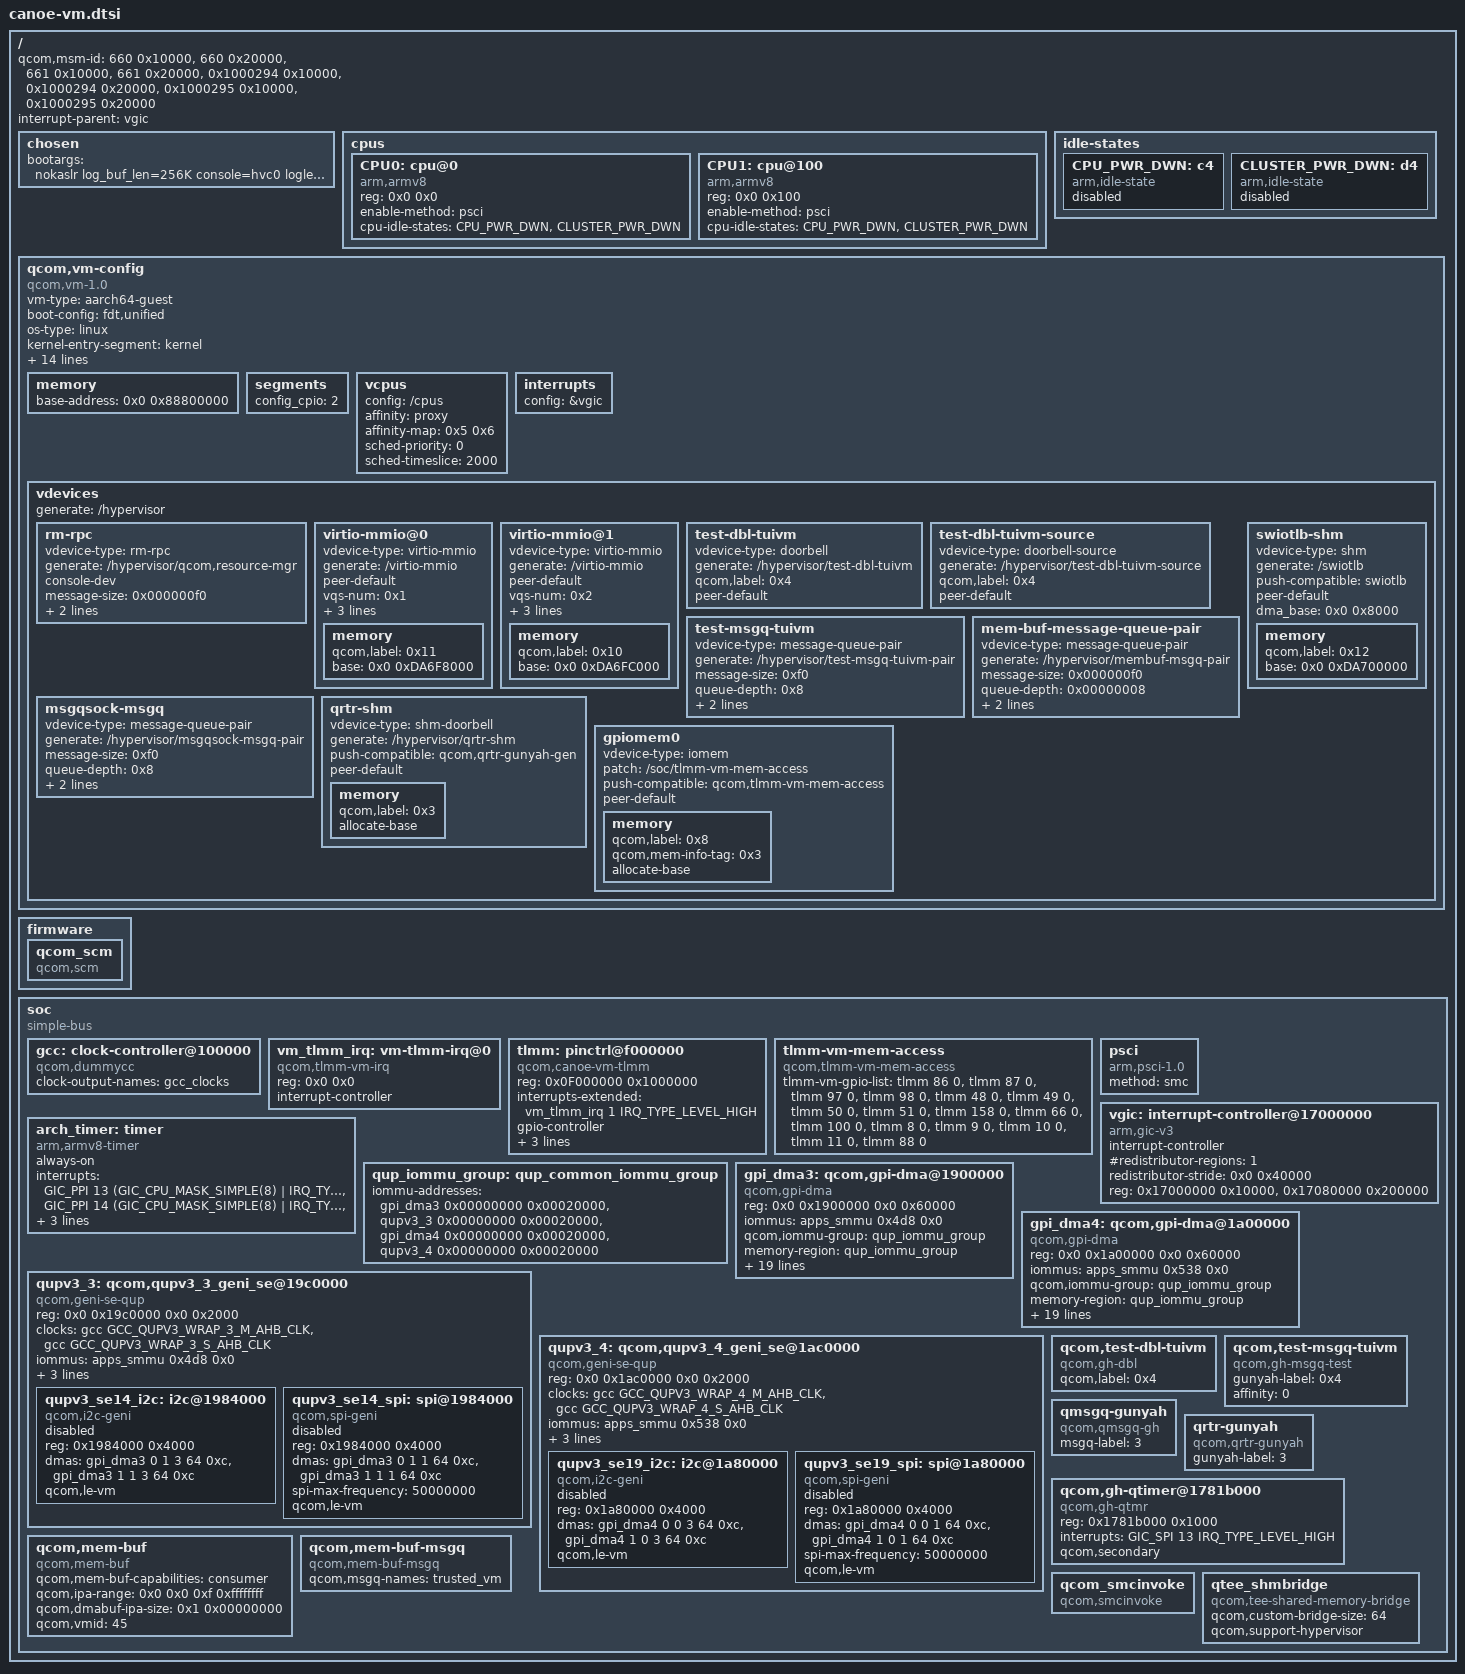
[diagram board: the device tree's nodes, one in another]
// SPDX-License-Identifier: BSD-3-Clause
/*
 * Copyright (c) 2024 Qualcomm Innovation Center, Inc. All rights reserved.
 */

#include <dt-bindings/clock/qcom,gcc-canoe.h>
#include <dt-bindings/interrupt-controller/arm-gic.h>

/ {
	#address-cells = <0x2>;
	#size-cells = <0x2>;
	qcom,msm-id = <660 0x10000>, <660 0x20000>, <661 0x10000>, <661 0x20000>,
		      <0x1000294 0x10000>, <0x1000294 0x20000>,
		      <0x1000295 0x10000>, <0x1000295 0x20000>;
	interrupt-parent = <&vgic>;

	chosen {
		bootargs = "nokaslr log_buf_len=256K console=hvc0 loglevel=8 swiotlb=noforce";
	};

	cpus {
		#address-cells = <0x2>;
		#size-cells = <0x0>;

		CPU0: cpu@0 {
			compatible = "arm,armv8";
			reg = <0x0 0x0>;
			device_type = "cpu";
			enable-method = "psci";
			cpu-idle-states = <&CPU_PWR_DWN
					   &CLUSTER_PWR_DWN>;
		};

		CPU1: cpu@100 {
			compatible = "arm,armv8";
			reg = <0x0 0x100>;
			device_type = "cpu";
			enable-method = "psci";
			cpu-idle-states = <&CPU_PWR_DWN
					   &CLUSTER_PWR_DWN>;

		};
	};

	idle-states {
		CPU_PWR_DWN: c4 {  /* Using Gold C4 latencies */
			compatible = "arm,idle-state";
			status = "disabled";
		};

		CLUSTER_PWR_DWN: d4 { /* C4+D4 */
			compatible = "arm,idle-state";
			status = "disabled";
		};
	};

	qcom,vm-config {
		compatible = "qcom,vm-1.0";
		vm-type = "aarch64-guest";
		boot-config = "fdt,unified";
		os-type = "linux";
		kernel-entry-segment = "kernel";
		kernel-entry-offset = <0x0 0x0>;
		vendor = "QTI";
		image-name = "qcom,trustedvm";
		qcom,pasid = <0x0 0x1c>;
		qcom,qtee-config-info = "p=3,9,39,77,78,7C,8F,97,C8,FE,11B,159,199,47E,7F1,CDF;";
		qcom,secdomain-ids = <45>;
		qcom,primary-vm-index = <0>;
		vm-uri = "vmuid/trusted-ui";
		vm-guid = "598085da-c516-5b25-a9c1-927a02819770";

		vm-attrs = "crash-fatal", "context-dump";

		iomemory-ranges = <0x0 0x1924000 0x0 0x1924000 0x0 0x4000 0x0
				0x0 0x1a24000 0x0 0x1a24000 0x0 0x4000 0x0>;

		/* For LEVM por usecases are QUP3_SE1 and QUP4_SE0.
		 * QUP3: SE1: GPII5 : IRQ_625
		 * QUP4: SE0: GPII5 : IRQ_541
		 */
		gic-irq-ranges = <541 541
				  625 625>; /* PVM->SVM IRQ transfer */

		memory {
			#address-cells = <0x2>;
			#size-cells = <0x0>;
			/*
			 * IPA address linux image is loaded at. Must be within
			 * first 1GB due to memory hotplug requirement.
			 */
			base-address = <0x0 0x88800000 >;
		};

		segments {
			config_cpio = <2>;
		};

		vcpus {
			config = "/cpus";
			affinity = "proxy";
			affinity-map = <0x5 0x6>;
			sched-priority = <0>;       /* relative to PVM */
			sched-timeslice = <2000>;   /* in ms */
		};

		interrupts {
			config = &vgic;
		};

		vdevices {
			generate = "/hypervisor";

			rm-rpc {
				vdevice-type = "rm-rpc";
				generate = "/hypervisor/qcom,resource-mgr";
				console-dev;
				message-size = <0x000000f0>;
				queue-depth = <0x00000008>;
				qcom,label = <0x1>;
			};

			virtio-mmio@0 {
				vdevice-type = "virtio-mmio";
				generate = "/virtio-mmio";
				peer-default;
				vqs-num = <0x1>;
				push-compatible = "virtio,mmio";
				dma-coherent;
				dma_base = <0x0 0x0>;
				memory {
					qcom,label = <0x11>;			//for persist.img
					#address-cells = <0x2>;
					base = <0x0 0xDA6F8000>;
				};
			};

			virtio-mmio@1 {
				vdevice-type = "virtio-mmio";
				generate = "/virtio-mmio";
				peer-default;
				vqs-num = <0x2>;
				push-compatible = "virtio,mmio";
				dma-coherent;
				dma_base = <0x0 0x4000>;
				memory {
					qcom,label = <0x10>;			//for system.img
					#address-cells = <0x2>;
					base = <0x0 0xDA6FC000>;
				};
			};

			test-dbl-tuivm {
				vdevice-type = "doorbell";
				generate = "/hypervisor/test-dbl-tuivm";
				qcom,label = <0x4>;
				peer-default;
			};

			test-dbl-tuivm-source {
				vdevice-type = "doorbell-source";
				generate = "/hypervisor/test-dbl-tuivm-source";
				qcom,label = <0x4>;
				peer-default;
			};

			test-msgq-tuivm {
				vdevice-type = "message-queue-pair";
				generate = "/hypervisor/test-msgq-tuivm-pair";
				message-size = <0xf0>;
				queue-depth = <0x8>;
				qcom,label = <0x4>;
				peer-default;
			};

			mem-buf-message-queue-pair {
				vdevice-type = "message-queue-pair";
				generate = "/hypervisor/membuf-msgq-pair";
				message-size = <0x000000f0>;
				queue-depth = <0x00000008>;
				peer-default;
				qcom,label = <0x0000001>;
			};

			msgqsock-msgq {
				vdevice-type = "message-queue-pair";
				generate = "/hypervisor/msgqsock-msgq-pair";
				message-size = <0xf0>;
				queue-depth = <0x8>;
				peer = "vm-name:qcom,oemvm";
				qcom,label = <0x3>;
			};

			swiotlb-shm {
				vdevice-type = "shm";
				generate = "/swiotlb";
				push-compatible = "swiotlb";
				peer-default;
				dma_base = <0x0 0x8000>;
				memory {
					qcom,label = <0x12>;
					#address-cells = <0x2>;
					base = <0x0 0xDA700000>;
				};
			};

			qrtr-shm {
				vdevice-type = "shm-doorbell";
				generate = "/hypervisor/qrtr-shm";
				push-compatible = "qcom,qrtr-gunyah-gen";
				peer-default;
				memory {
					qcom,label = <0x3>;
					allocate-base;
				};
			};

			gpiomem0 {
				vdevice-type = "iomem";
				patch = "/soc/tlmm-vm-mem-access";
				push-compatible = "qcom,tlmm-vm-mem-access";
				peer-default;
				memory {
					qcom,label = <0x8>;
					qcom,mem-info-tag = <0x3>;
					allocate-base;
				};
			};

		};
	};

	firmware: firmware {
		qcom_scm: qcom_scm {
			compatible = "qcom,scm";
		};
	};

	soc: soc { };
};

&soc {
	#address-cells = <1>;
	#size-cells = <1>;
	ranges = <0 0 0 0xffffffff>;
	compatible = "simple-bus";

	gcc: clock-controller@100000 {
		compatible = "qcom,dummycc";
		clock-output-names = "gcc_clocks";
		#clock-cells = <1>;
		#reset-cells = <1>;
	};

	vm_tlmm_irq: vm-tlmm-irq@0 {
		compatible = "qcom,tlmm-vm-irq";
		reg = <0x0 0x0>;
		interrupt-controller;
		#interrupt-cells = <2>;
	};

	tlmm: pinctrl@f000000 {
		compatible = "qcom,canoe-vm-tlmm";
		reg = <0x0F000000 0x1000000>;
		interrupts-extended = <&vm_tlmm_irq 1 IRQ_TYPE_LEVEL_HIGH>;
		gpio-controller;
		#gpio-cells = <2>;
		interrupt-controller;
		#interrupt-cells = <2>;
		/* Valid pins */
		gpios = /bits/ 16 <86 87 97 98 48 49 50 51 158 66 100 8 9 10 11 88>;
	};

	tlmm-vm-mem-access {
		compatible = "qcom,tlmm-vm-mem-access";
		tlmm-vm-gpio-list = <&tlmm 86 0 &tlmm 87 0 &tlmm 97 0 &tlmm 98 0 &tlmm 48 0
					&tlmm 49 0 &tlmm 50 0 &tlmm 51 0 &tlmm 158 0 &tlmm 66 0
					&tlmm 100 0 &tlmm 8 0 &tlmm 9 0 &tlmm 10 0 &tlmm 11 0
					&tlmm 88 0>;
	};

	psci {
		compatible = "arm,psci-1.0";
		method = "smc";
	};

	vgic: interrupt-controller@17000000 {
		compatible = "arm,gic-v3";
		#interrupt-cells = <3>;
		interrupt-controller;
		#redistributor-regions = <1>;
		redistributor-stride = <0x0 0x40000>;
		reg = <0x17000000 0x10000>,	/* GICD */
		      <0x17080000 0x200000>;	/* GICR * 8 */
	};

	arch_timer: timer {
		compatible = "arm,armv8-timer";
		always-on;
		interrupts = <GIC_PPI 13 (GIC_CPU_MASK_SIMPLE(8) | IRQ_TYPE_LEVEL_LOW)>,
			     <GIC_PPI 14 (GIC_CPU_MASK_SIMPLE(8) | IRQ_TYPE_LEVEL_LOW)>,
			     <GIC_PPI 11 (GIC_CPU_MASK_SIMPLE(8) | IRQ_TYPE_LEVEL_LOW)>,
			     <GIC_PPI 12 (GIC_CPU_MASK_SIMPLE(8) | IRQ_TYPE_LEVEL_LOW)>;
		clock-frequency = <19200000>;
	};

	/*
	 * QUP4 : SE0 - Primary touch
	 * QUP3 : SE1 - Secondary touch
	 */
	qup_iommu_group: qup_common_iommu_group {
		iommu-addresses = <&gpi_dma3 0x00000000 0x00020000>,
				<&qupv3_3 0x00000000 0x00020000>,
				<&gpi_dma4 0x00000000 0x00020000>,
				<&qupv3_4 0x00000000 0x00020000>;
	};

	/* GPI Instance */
	gpi_dma3: qcom,gpi-dma@1900000 {
		compatible = "qcom,gpi-dma";
		#dma-cells = <5>;
		reg = <0x0 0x1900000 0x0 0x60000>;
		reg-names = "gpi-top";
		iommus = <&apps_smmu 0x4d8 0x0>;
		qcom,iommu-group = <&qup_iommu_group>;
		memory-region = <&qup_iommu_group>;
		dma-coherent;
		interrupts = <GIC_SPI 588 IRQ_TYPE_LEVEL_HIGH>,
			<GIC_SPI 589 IRQ_TYPE_LEVEL_HIGH>,
			<GIC_SPI 590 IRQ_TYPE_LEVEL_HIGH>,
			<GIC_SPI 591 IRQ_TYPE_LEVEL_HIGH>,
			<GIC_SPI 592 IRQ_TYPE_LEVEL_HIGH>,
			<GIC_SPI 593 IRQ_TYPE_LEVEL_HIGH>,
			<GIC_SPI 594 IRQ_TYPE_LEVEL_HIGH>,
			<GIC_SPI 595 IRQ_TYPE_LEVEL_HIGH>,
			<GIC_SPI 596 IRQ_TYPE_LEVEL_HIGH>,
			<GIC_SPI 597 IRQ_TYPE_LEVEL_HIGH>,
			<GIC_SPI 598 IRQ_TYPE_LEVEL_HIGH>,
			<GIC_SPI 599 IRQ_TYPE_LEVEL_HIGH>;
		qcom,max-num-gpii = <12>;
		qcom,static-gpii-mask = <0x20>;
		qcom,gpii-mask = <0x0>;
		qcom,ev-factor = <1>;
		qcom,gpi-ee-offset = <0x10000>;
		qcom,le-vm;
		status = "ok";
	};

	/* QUPv3_3 wrapper instance */
	qupv3_3: qcom,qupv3_3_geni_se@19c0000 {
		compatible = "qcom,geni-se-qup";
		reg = <0x0 0x19c0000 0x0 0x2000>;
		#address-cells = <1>;
		#size-cells = <1>;
		clock-names = "m-ahb", "s-ahb";
		clocks = <&gcc GCC_QUPV3_WRAP_3_M_AHB_CLK>,
			<&gcc GCC_QUPV3_WRAP_3_S_AHB_CLK>;
		iommus = <&apps_smmu 0x4d8 0x0>;
		qcom,iommu-group = <&qup_iommu_group>;
		memory-region = <&qup_iommu_group>;
		dma-coherent;
		ranges;
		status = "ok";

		qupv3_se14_i2c: i2c@1984000 {
			compatible = "qcom,i2c-geni";
			reg = <0x1984000 0x4000>;
			#address-cells = <1>;
			#size-cells = <0>;
			dmas = <&gpi_dma3 0 1 3 64 0xc>,
				<&gpi_dma3 1 1 3 64 0xc>;
			dma-names = "tx", "rx";
			qcom,le-vm;
			status = "disabled";
		};

		qupv3_se14_spi: spi@1984000 {
			compatible = "qcom,spi-geni";
			reg = <0x1984000 0x4000>;
			#address-cells = <1>;
			#size-cells = <0>;
			reg-names = "se_phys";
			dmas = <&gpi_dma3 0 1 1 64 0xc>,
				<&gpi_dma3 1 1 1 64 0xc>;
			dma-names = "tx", "rx";
			spi-max-frequency = <50000000>;
			qcom,le-vm;
			status = "disabled";
		};
	};

	/* GPI Instance */
	gpi_dma4: qcom,gpi-dma@1a00000 {
		compatible = "qcom,gpi-dma";
		#dma-cells = <5>;
		reg = <0x0 0x1a00000 0x0 0x60000>;
		reg-names = "gpi-top";
		iommus = <&apps_smmu 0x538 0x0>;
		qcom,iommu-group = <&qup_iommu_group>;
		memory-region = <&qup_iommu_group>;
		dma-coherent;
		interrupts = <GIC_SPI 504 IRQ_TYPE_LEVEL_HIGH>,
			<GIC_SPI 505 IRQ_TYPE_LEVEL_HIGH>,
			<GIC_SPI 506 IRQ_TYPE_LEVEL_HIGH>,
			<GIC_SPI 507 IRQ_TYPE_LEVEL_HIGH>,
			<GIC_SPI 508 IRQ_TYPE_LEVEL_HIGH>,
			<GIC_SPI 509 IRQ_TYPE_LEVEL_HIGH>,
			<GIC_SPI 510 IRQ_TYPE_LEVEL_HIGH>,
			<GIC_SPI 511 IRQ_TYPE_LEVEL_HIGH>,
			<GIC_SPI 512 IRQ_TYPE_LEVEL_HIGH>,
			<GIC_SPI 513 IRQ_TYPE_LEVEL_HIGH>,
			<GIC_SPI 514 IRQ_TYPE_LEVEL_HIGH>,
			<GIC_SPI 515 IRQ_TYPE_LEVEL_HIGH>;
		qcom,max-num-gpii = <12>;
		qcom,static-gpii-mask = <0x20>;
		qcom,gpii-mask = <0x0>;
		qcom,ev-factor = <1>;
		qcom,gpi-ee-offset = <0x10000>;
		qcom,le-vm;
		status = "ok";
	};

	/* QUPv3_4 wrapper instance */
	qupv3_4: qcom,qupv3_4_geni_se@1ac0000 {
		compatible = "qcom,geni-se-qup";
		reg = <0x0 0x1ac0000 0x0 0x2000>;
		#address-cells = <1>;
		#size-cells = <1>;
		clock-names = "m-ahb", "s-ahb";
		clocks = <&gcc GCC_QUPV3_WRAP_4_M_AHB_CLK>,
			<&gcc GCC_QUPV3_WRAP_4_S_AHB_CLK>;
		iommus = <&apps_smmu 0x538 0x0>;
		qcom,iommu-group = <&qup_iommu_group>;
		memory-region = <&qup_iommu_group>;
		dma-coherent;
		ranges;
		status = "ok";

		qupv3_se19_i2c: i2c@1a80000 {
			compatible = "qcom,i2c-geni";
			reg = <0x1a80000 0x4000>;
			#address-cells = <1>;
			#size-cells = <0>;
			dmas = <&gpi_dma4 0 0 3 64 0xc>,
				<&gpi_dma4 1 0 3 64 0xc>;
			dma-names = "tx", "rx";
			qcom,le-vm;
			status = "disabled";
		};

		qupv3_se19_spi: spi@1a80000 {
			compatible = "qcom,spi-geni";
			reg = <0x1a80000 0x4000>;
			#address-cells = <1>;
			#size-cells = <0>;
			reg-names = "se_phys";
			dmas = <&gpi_dma4 0 0 1 64 0xc>,
				<&gpi_dma4 1 0 1 64 0xc>;
			dma-names = "tx", "rx";
			spi-max-frequency = <50000000>;
			qcom,le-vm;
			status = "disabled";
		};
	};

	qcom,test-dbl-tuivm {
		compatible = "qcom,gh-dbl";
		qcom,label = <0x4>;
	};

	qcom,test-msgq-tuivm {
		compatible = "qcom,gh-msgq-test";
		gunyah-label = <0x4>;
		affinity = <0>;
	};

	qmsgq-gunyah {
		compatible = "qcom,qmsgq-gh";
		msgq-label = <3>;
	};

	qrtr-gunyah {
		compatible = "qcom,qrtr-gunyah";
		gunyah-label = <3>;
	};

	qcom,gh-qtimer@1781b000 {
		compatible = "qcom,gh-qtmr";
		reg = <0x1781b000 0x1000>;
		reg-names = "qtmr-base";
		interrupts = <GIC_SPI 13 IRQ_TYPE_LEVEL_HIGH>;
		interrupt-names = "qcom,qtmr-intr";
		qcom,secondary;
	};

	qcom,mem-buf {
		compatible = "qcom,mem-buf";
		qcom,mem-buf-capabilities = "consumer";
		qcom,ipa-range = <0x0 0x0 0xf 0xffffffff>;
		qcom,dmabuf-ipa-size = <0x1 0x00000000>; /* 4GB IPA space for dmabuf */
		qcom,vmid = <45>;
	};

	qcom,mem-buf-msgq {
		compatible = "qcom,mem-buf-msgq";
		qcom,msgq-names = "trusted_vm";
	};

	qcom_smcinvoke {
		compatible = "qcom,smcinvoke";
	};

	qtee_shmbridge {
		compatible = "qcom,tee-shared-memory-bridge";
		qcom,custom-bridge-size = <64>;
		qcom,support-hypervisor;
	};

};

#include "msm-arm-smmu-canoe-vm.dtsi"
#include "canoe-vm-dma-heaps.dtsi"
